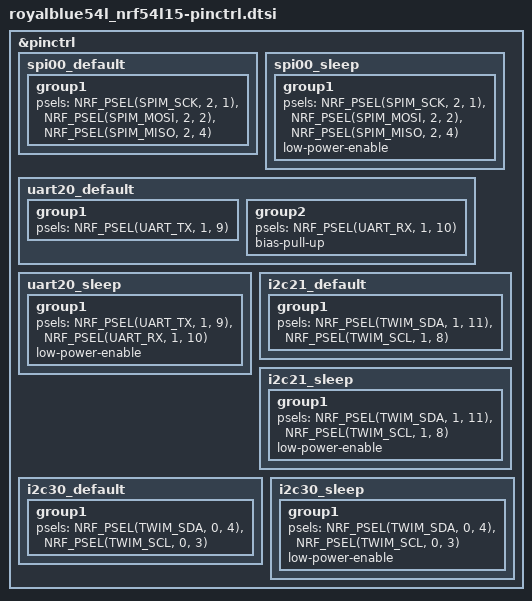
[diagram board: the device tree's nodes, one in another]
/*
 * Copyright (c) 2024 Nordic Semiconductor
 * SPDX-License-Identifier: Apache-2.0
 */

&pinctrl {
	/omit-if-no-ref/ spi00_default: spi00_default {
		group1 {
			psels = <NRF_PSEL(SPIM_SCK, 2, 1)>,
				<NRF_PSEL(SPIM_MOSI, 2, 2)>,
				<NRF_PSEL(SPIM_MISO, 2, 4)>;
		};
	};

	/omit-if-no-ref/ spi00_sleep: spi00_sleep {
		group1 {
			psels = <NRF_PSEL(SPIM_SCK, 2, 1)>,
				<NRF_PSEL(SPIM_MOSI, 2, 2)>,
				<NRF_PSEL(SPIM_MISO, 2, 4)>;
				low-power-enable;
		};
	};

	/omit-if-no-ref/ uart20_default: uart20_default {
		group1 {
			psels = <NRF_PSEL(UART_TX, 1, 9)>;
		};
		group2 {
			psels = <NRF_PSEL(UART_RX, 1, 10)>;
			bias-pull-up;
		};
	};

	/omit-if-no-ref/ uart20_sleep: uart20_sleep {
		group1 {
			psels = <NRF_PSEL(UART_TX, 1, 9)>,
				<NRF_PSEL(UART_RX, 1, 10)>;
			low-power-enable;
		};
	};

	/omit-if-no-ref/ i2c21_default: i2c21_default {
		group1 {
			psels = <NRF_PSEL(TWIM_SDA, 1, 11)>,
				<NRF_PSEL(TWIM_SCL, 1, 8)>;
		};
	};

	/omit-if-no-ref/ i2c21_sleep: i2c21_sleep {
		group1 {
			psels = <NRF_PSEL(TWIM_SDA, 1, 11)>,
				<NRF_PSEL(TWIM_SCL, 1, 8)>;
			low-power-enable;
		};
	};

	/omit-if-no-ref/ i2c30_default: i2c30_default {
		group1 {
			psels = <NRF_PSEL(TWIM_SDA, 0, 4)>,
				<NRF_PSEL(TWIM_SCL, 0, 3)>;
		};
	};

	/omit-if-no-ref/ i2c30_sleep: i2c30_sleep {
		group1 {
			psels = <NRF_PSEL(TWIM_SDA, 0, 4)>,
				<NRF_PSEL(TWIM_SCL, 0, 3)>;
			low-power-enable;
		};
	};
};
